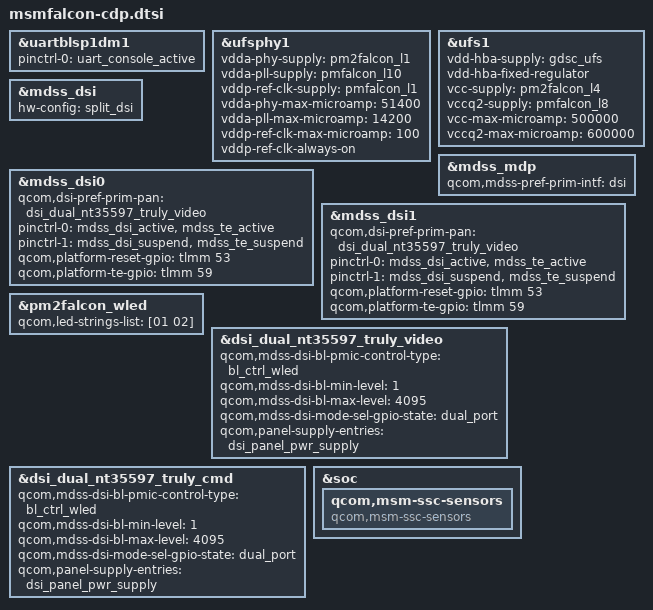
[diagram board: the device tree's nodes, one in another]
/* Copyright (c) 2016, The Linux Foundation. All rights reserved.
 *
 * This program is free software; you can redistribute it and/or modify
 * it under the terms of the GNU General Public License version 2 and
 * only version 2 as published by the Free Software Foundation.
 *
 * This program is distributed in the hope that it will be useful,
 * but WITHOUT ANY WARRANTY; without even the implied warranty of
 * MERCHANTABILITY or FITNESS FOR A PARTICULAR PURPOSE.  See the
 * GNU General Public License for more details.
 */

#include "msmfalcon-pinctrl.dtsi"
#include "msmfalcon-camera-sensor-cdp.dtsi"
/ {
};

&uartblsp1dm1 {
	status = "ok";
	pinctrl-names = "default";
	pinctrl-0 = <&uart_console_active>;
};

&ufsphy1 {
	vdda-phy-supply = <&pm2falcon_l1>;
	vdda-pll-supply = <&pmfalcon_l10>;
	vddp-ref-clk-supply = <&pmfalcon_l1>;
	vdda-phy-max-microamp = <51400>;
	vdda-pll-max-microamp = <14200>;
	vddp-ref-clk-max-microamp = <100>;
	vddp-ref-clk-always-on;
	status = "ok";
};

&ufs1 {
	vdd-hba-supply = <&gdsc_ufs>;
	vdd-hba-fixed-regulator;
	vcc-supply = <&pm2falcon_l4>;
	vccq2-supply = <&pmfalcon_l8>;
	vcc-max-microamp = <500000>;
	vccq2-max-microamp = <600000>;
	status = "ok";
};

&mdss_mdp {
	qcom,mdss-pref-prim-intf = "dsi";
};

&mdss_dsi {
	hw-config = "split_dsi";
};

&mdss_dsi0 {
	qcom,dsi-pref-prim-pan = <&dsi_dual_nt35597_truly_video>;
	pinctrl-names = "mdss_default", "mdss_sleep";
	pinctrl-0 = <&mdss_dsi_active &mdss_te_active>;
	pinctrl-1 = <&mdss_dsi_suspend &mdss_te_suspend>;
	qcom,platform-reset-gpio = <&tlmm 53 0>;
	qcom,platform-te-gpio = <&tlmm 59 0>;
};

&mdss_dsi1 {
	qcom,dsi-pref-prim-pan = <&dsi_dual_nt35597_truly_video>;
	pinctrl-names = "mdss_default", "mdss_sleep";
	pinctrl-0 = <&mdss_dsi_active &mdss_te_active>;
	pinctrl-1 = <&mdss_dsi_suspend &mdss_te_suspend>;
	qcom,platform-reset-gpio = <&tlmm 53 0>;
	qcom,platform-te-gpio = <&tlmm 59 0>;
};

&pm2falcon_wled {
	qcom,led-strings-list = [01 02];
};

&dsi_dual_nt35597_truly_video {
	qcom,mdss-dsi-bl-pmic-control-type = "bl_ctrl_wled";
	qcom,mdss-dsi-bl-min-level = <1>;
	qcom,mdss-dsi-bl-max-level = <4095>;
	qcom,mdss-dsi-mode-sel-gpio-state = "dual_port";
	qcom,panel-supply-entries = <&dsi_panel_pwr_supply>;
};

&dsi_dual_nt35597_truly_cmd {
	qcom,mdss-dsi-bl-pmic-control-type = "bl_ctrl_wled";
	qcom,mdss-dsi-bl-min-level = <1>;
	qcom,mdss-dsi-bl-max-level = <4095>;
	qcom,mdss-dsi-mode-sel-gpio-state = "dual_port";
	qcom,panel-supply-entries = <&dsi_panel_pwr_supply>;
};

&soc {
	qcom,msm-ssc-sensors {
		compatible = "qcom,msm-ssc-sensors";
	};
};
